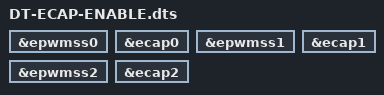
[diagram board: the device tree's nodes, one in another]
/dts-v1/;
/{
/* module 1 */
    fragment@0 {
        target = <&epwmss0>;
        __overlay__ {
            status = "okay";
        };
    };

    fragment@1 {
        target = <&ecap0>;
        __overlay__ {
            status = "okay";
        };
    };


/* module 2 */
    fragment@2 {
        target = <&epwmss1>;
        __overlay__ {
            status = "okay";
        };
    };

    fragment@3 {
        target = <&ecap1>;
        __overlay__ {
            status = "okay";
        };
    };

/* module 3 */
    fragment@4 {
        target = <&epwmss2>;
        __overlay__ {
            status = "okay";
        };
    };

    fragment@5 {
        target = <&ecap2>;
        __overlay__ {
            status = "okay";
        };
    };


};
